# RS1xxxx register map
Vendor: Silicon Lab Inc.; Series: ARMCM4; File version: 1.2
CPU: CM4 r1p0, little endian, MPU, FPU, 6 interrupt priority bits
Registers are 32-bit, read-write, reset 0x0 unless marked. A register's access mark holds for its fields unless they carry their own. Offsets are from the block's base; [hi:lo] are bit positions.

## Calendar — The MCU calendar acts as RTC with time in seconds, minutes, hours, days, months, years and centuries
Base 0x24048200
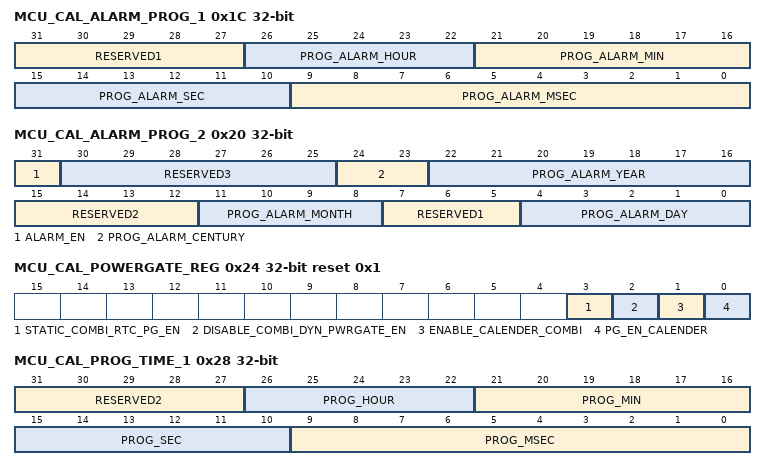
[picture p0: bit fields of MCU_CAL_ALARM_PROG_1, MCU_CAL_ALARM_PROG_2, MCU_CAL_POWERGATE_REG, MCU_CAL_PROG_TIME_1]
0x1C MCU_CAL_ALARM_PROG_1 — MCU calender alarm prog register 1
  [31:27] RESERVED1 ro — reser
  [26:22] PROG_ALARM_HOUR — hours value of alarm time
  [21:16] PROG_ALARM_MIN — mins value of alarm time
  [15:10] PROG_ALARM_SEC — seconds value of alarm time
  [9:0] PROG_ALARM_MSEC — milli seconds value of alarm time
0x20 MCU_CAL_ALARM_PROG_2 — MCU calender alarm prog register 2
  [31] ALARM_EN — alarm function enable for calendar
  [30:25] RESERVED3 ro — reser
  [24:23] PROG_ALARM_CENTURY — century count in alarm time
  [22:16] PROG_ALARM_YEAR — year count in alarm time 0 - 99
  [15:12] RESERVED2 ro — reser
  [11:8] PROG_ALARM_MONTH — month count in alarm time
  [7:5] RESERVED1 ro — reser
  [4:0] PROG_ALARM_DAY — day count in alarm time 1-31
0x24 MCU_CAL_POWERGATE_REG reset 0x1 — MCU calender powergate register
  [3] STATIC_COMBI_RTC_PG_EN — Enable static combo RTC power gate
  [2] DISABLE_COMBI_DYN_PWRGATE_EN — Disable option for dynamic combo RTC power gate
  [1] ENABLE_CALENDER_COMBI — Enable calender combitional logic block
  [0] PG_EN_CALENDER — Start calender block
0x28 MCU_CAL_PROG_TIME_1 — MCU calendar prog time 1 register
  [31:27] RESERVED2 ro — reser
  [26:22] PROG_HOUR — hours value to be programmed to real time in calendar when pro_time_trig is 1
  [21:16] PROG_MIN — minutes value to be programmed to real time in calendar when pro_time_trig is 1
  [15:10] PROG_SEC — seconds value to be programmed to real time in calendar when pro_time_trig is 1
  [9:0] PROG_MSEC — Milli seconds value to be programmed to real time in calendar when pro_time_trig is 1
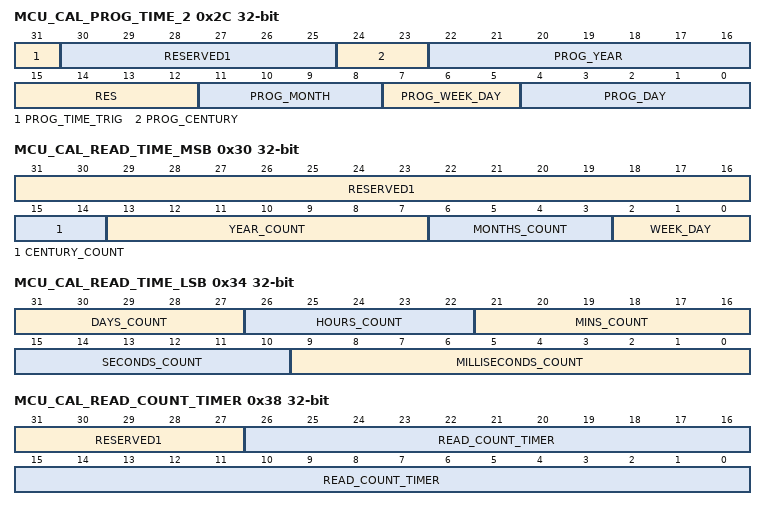
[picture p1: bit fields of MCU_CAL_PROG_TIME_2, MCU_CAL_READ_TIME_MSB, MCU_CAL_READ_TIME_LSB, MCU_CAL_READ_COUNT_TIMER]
0x2C MCU_CAL_PROG_TIME_2 — MCU calendar prog time 2 register
  [31] PROG_TIME_TRIG wo — load the programmed to the real time in calendar block
  [30:25] RESERVED1 ro — reser
  [24:23] PROG_CENTURY — century value to be programmed to real time in calendar when pro_time_trig is 1
  [22:16] PROG_YEAR — year value to be programmed to real time in calendar when pro_time_trig is 1
  [15:12] RES ro — reser
  [11:8] PROG_MONTH — month value to be programmed to real time in calendar when pro_time_trig is 1
  [7:5] PROG_WEEK_DAY — program which week day it is
  [4:0] PROG_DAY — day count value to be programmed to real time in calendar when pro_time_trig is 1
0x30 MCU_CAL_READ_TIME_MSB ro — MCU calendar read time msb
  [31:16] RESERVED1 — reser
  [15:14] CENTURY_COUNT
  [13:7] YEAR_COUNT — years count
  [6:3] MONTHS_COUNT
  [2:0] WEEK_DAY
0x34 MCU_CAL_READ_TIME_LSB ro — MCU calendar read time lsb
  [31:27] DAYS_COUNT, [26:22] HOURS_COUNT, [21:16] MINS_COUNT, [15:10] SECONDS_COUNT, [9:0] MILLISECONDS_COUNT
0x38 MCU_CAL_READ_COUNT_TIMER ro — MCU calendar read count timer
  [31:27] RESERVED1 — reser
  [26:0] READ_COUNT_TIMER — Read timer which increments by time period value to reach to count milliseconds
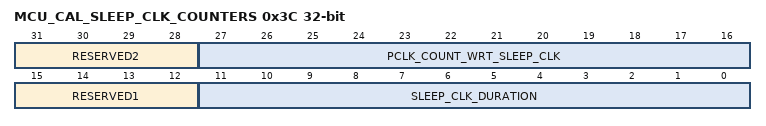
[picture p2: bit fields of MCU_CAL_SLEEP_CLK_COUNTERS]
0x3C MCU_CAL_SLEEP_CLK_COUNTERS ro — MCU calendar sleep clock counter
  [31:28] RESERVED2 — reser
  [27:16] PCLK_COUNT_WRT_SLEEP_CLK — no. of APB clks in 1 sleep clock duration
  [15:12] RESERVED1 — reser
  [11:0] SLEEP_CLK_DURATION — No of sleep clks with respect to APB clock so far from the posedge of sleep clk
0x40 MCU_CAL_KEY_EANBLE wo reset 0x55555555 — MCU calendar key enable
  [31:0] RTC_KEY — enable access to program Watch dog registers

## MCU_ProcessSensor — The process sensor module, count the process clock (high frequency ring clock) over one MCU FSM clock and divide this clock by programmable value.
Base 0x24048540
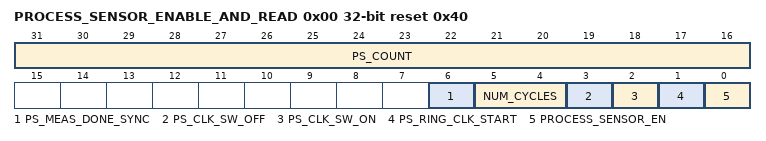
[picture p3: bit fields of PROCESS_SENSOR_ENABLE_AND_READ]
0x00 PROCESS_SENSOR_ENABLE_AND_READ reset 0x40 — Process sensor enable and read for operation
  [31:16] PS_COUNT ro — Processor sensor read back
  [6] PS_MEAS_DONE_SYNC ro — Processor sensor measurement done.
  [5:4] NUM_CYCLES — Number of MCU FSM clock(32KHz)for which measurement need to be done.if bits is 1 then 1 clock, 2 then 2 clocks,3 then 3 clocks,4 then 4 clocks.
  [3] PS_CLK_SW_OFF — Clock cleaner off signal to clock cleaner block on clock generated by delay chain.
  [2] PS_CLK_SW_ON — Clock cleaner on signal to clock cleaner block on clock generated by delay chain.
  [1] PS_RING_CLK_START — Start Ring-Oscillator clock for estimating process corner.
  [0] PROCESS_SENSOR_EN — enable or on the process sensor,if this bit is set the sensor enable else sensor is disable.
